# ESP32-H2 register map
Vendor: ESPRESSIF SYSTEMS (SHANGHAI) CO., LTD.; Series: ESP32 H-Series; File version: 1
CPU: RV32IMC r0p0, little endian, no MPU, no FPU, 4 interrupt priority bits
Address unit: 32 bits
Registers are 32-bit, read-write, reset 0x0 unless marked. A register's access mark holds for its fields unless they carry their own. Offsets are from the block's base; [hi:lo] are bit positions; {n}, {i} and the like mark numbered series.

## SPI2 — SPI (Serial Peripheral Interface) Controller
Base 0x60024000
Same registers: SPI3 0x60025000, SPI4 0x60037000
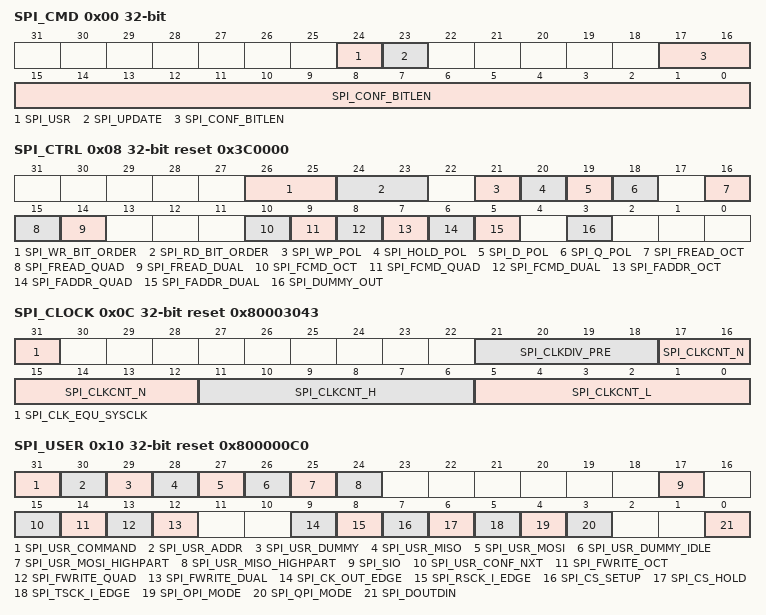
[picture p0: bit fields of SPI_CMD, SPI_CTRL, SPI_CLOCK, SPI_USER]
0x00 SPI_CMD access per field — Command control register
  [24] SPI_USR rw — User define command enable. An operation will be triggered when the bit is set. The bit will be cleared once the operation done.1: enable 0: disable. Can not be changed by CONF_buf.
  [23] SPI_UPDATE wo — Set this bit to synchronize SPI registers from APB clock domain into SPI module clock domain, which is only used in SPI master mode.
  [17:0] SPI_CONF_BITLEN rw — Define the APB cycles of SPI_CONF state. Can be configured in CONF state.
0x04 SPI_ADDR — Address value register
  [31:0] SPI_USR_ADDR_VALUE — Address to slave. Can be configured in CONF state.
0x08 SPI_CTRL access per field reset 0x3C0000 — SPI control register
  [26:25] SPI_WR_BIT_ORDER rw — In command address write-data (MOSI) phases 1: LSB firs 0: MSB first. Can be configured in CONF state.
  [24:23] SPI_RD_BIT_ORDER rw — In read-data (MISO) phase 1: LSB first 0: MSB first. Can be configured in CONF state.
  [21] SPI_WP_POL rw — Write protect signal output when SPI is idle. 1: output high, 0: output low. Can be configured in CONF state.
  [20] SPI_HOLD_POL rw — SPI_HOLD output value when SPI is idle. 1: output high, 0: output low. Can be configured in CONF state.
  [19] SPI_D_POL rw — The bit is used to set MOSI line polarity, 1: high 0, low. Can be configured in CONF state.
  [18] SPI_Q_POL rw — The bit is used to set MISO line polarity, 1: high 0, low. Can be configured in CONF state.
  [16] SPI_FREAD_OCT ro — In the read operations read-data phase apply 8 signals. 1: enable 0: disable. Can be configured in CONF state.
  [15] SPI_FREAD_QUAD rw — In the read operations read-data phase apply 4 signals. 1: enable 0: disable. Can be configured in CONF state.
  [14] SPI_FREAD_DUAL rw — In the read operations, read-data phase apply 2 signals. 1: enable 0: disable. Can be configured in CONF state.
  [10] SPI_FCMD_OCT ro — Apply 8 signals during command phase 1:enable 0: disable. Can be configured in CONF state.
  [9] SPI_FCMD_QUAD rw — Apply 4 signals during command phase 1:enable 0: disable. Can be configured in CONF state.
  [8] SPI_FCMD_DUAL rw — Apply 2 signals during command phase 1:enable 0: disable. Can be configured in CONF state.
  [7] SPI_FADDR_OCT ro — Apply 8 signals during addr phase 1:enable 0: disable. Can be configured in CONF state.
  [6] SPI_FADDR_QUAD rw — Apply 4 signals during addr phase 1:enable 0: disable. Can be configured in CONF state.
  [5] SPI_FADDR_DUAL rw — Apply 2 signals during addr phase 1:enable 0: disable. Can be configured in CONF state.
  [3] SPI_DUMMY_OUT rw — 0: In the dummy phase, the FSPI bus signals are not output. 1: In the dummy phase, the FSPI bus signals are output. Can be configured in CONF state.
0x0C SPI_CLOCK reset 0x80003043 — SPI clock control register
  [31] SPI_CLK_EQU_SYSCLK — In the master mode 1: spi_clk is eqaul to system 0: spi_clk is divided from system clock. Can be configured in CONF state.
  [21:18] SPI_CLKDIV_PRE — In the master mode it is pre-divider of spi_clk. Can be configured in CONF state.
  [17:12] SPI_CLKCNT_N — In the master mode it is the divider of spi_clk. So spi_clk frequency is system/(spi_clkdiv_pre+1)/(spi_clkcnt_N+1). Can be configured in CONF state.
  [11:6] SPI_CLKCNT_H — In the master mode it must be floor((spi_clkcnt_N+1)/2-1). In the slave mode it must be 0. Can be configured in CONF state.
  [5:0] SPI_CLKCNT_L — In the master mode it must be equal to spi_clkcnt_N. In the slave mode it must be 0. Can be configured in CONF state.
0x10 SPI_USER access per field reset 0x800000C0 — SPI USER control register
  [31] SPI_USR_COMMAND rw — This bit enable the command phase of an operation. Can be configured in CONF state.
  [30] SPI_USR_ADDR rw — This bit enable the address phase of an operation. Can be configured in CONF state.
  [29] SPI_USR_DUMMY rw — This bit enable the dummy phase of an operation. Can be configured in CONF state.
  [28] SPI_USR_MISO rw — This bit enable the read-data phase of an operation. Can be configured in CONF state.
  [27] SPI_USR_MOSI rw — This bit enable the write-data phase of an operation. Can be configured in CONF state.
  [26] SPI_USR_DUMMY_IDLE rw — spi clock is disable in dummy phase when the bit is enable. Can be configured in CONF state.
  [25] SPI_USR_MOSI_HIGHPART rw — write-data phase only access to high-part of the buffer spi_w8~spi_w15. 1: enable 0: disable. Can be configured in CONF state.
  [24] SPI_USR_MISO_HIGHPART rw — read-data phase only access to high-part of the buffer spi_w8~spi_w15. 1: enable 0: disable. Can be configured in CONF state.
  [17] SPI_SIO rw — Set the bit to enable 3-line half duplex communication mosi and miso signals share the same pin. 1: enable 0: disable. Can be configured in CONF state.
  [15] SPI_USR_CONF_NXT rw — 1: Enable the DMA CONF phase of next seg-trans operation, which means seg-trans will continue. 0: The seg-trans will end after the current SPI seg-trans or this is not seg-trans mode. Can be configured in CONF state.
  [14] SPI_FWRITE_OCT ro — In the write operations read-data phase apply 8 signals. Can be configured in CONF state.
  [13] SPI_FWRITE_QUAD rw — In the write operations read-data phase apply 4 signals. Can be configured in CONF state.
  [12] SPI_FWRITE_DUAL rw — In the write operations read-data phase apply 2 signals. Can be configured in CONF state.
  [9] SPI_CK_OUT_EDGE rw — the bit combined with spi_mosi_delay_mode bits to set mosi signal delay mode. Can be configured in CONF state.
  [8] SPI_RSCK_I_EDGE rw — In the slave mode, this bit can be used to change the polarity of rsck. 0: rsck = !spi_ck_i. 1:rsck = spi_ck_i.
  [7] SPI_CS_SETUP rw — spi cs is enable when spi is in prepare phase. 1: enable 0: disable. Can be configured in CONF state.
  [6] SPI_CS_HOLD rw — spi cs keep low when spi is in done phase. 1: enable 0: disable. Can be configured in CONF state.
  [5] SPI_TSCK_I_EDGE rw — In the slave mode, this bit can be used to change the polarity of tsck. 0: tsck = spi_ck_i. 1:tsck = !spi_ck_i.
  [4] SPI_OPI_MODE ro — Just for master mode. 1: spi controller is in OPI mode (all in 8-b-m). 0: others. Can be configured in CONF state.
  [3] SPI_QPI_MODE rw — Both for master mode and slave mode. 1: spi controller is in QPI mode. 0: others. Can be configured in CONF state.
  [0] SPI_DOUTDIN rw — Set the bit to enable full duplex communication. 1: enable 0: disable. Can be configured in CONF state.
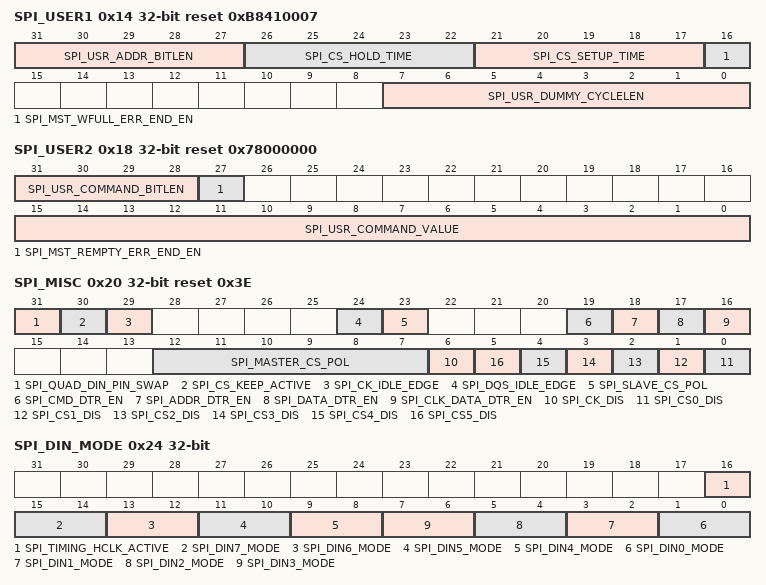
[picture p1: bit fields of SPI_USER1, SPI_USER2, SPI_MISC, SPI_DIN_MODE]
0x14 SPI_USER1 reset 0xB8410007 — SPI USER control register 1
  [31:27] SPI_USR_ADDR_BITLEN — The length in bits of address phase. The register value shall be (bit_num-1). Can be configured in CONF state.
  [26:22] SPI_CS_HOLD_TIME — delay cycles of cs pin by spi clock this bits are combined with spi_cs_hold bit. Can be configured in CONF state.
  [21:17] SPI_CS_SETUP_TIME — (cycles+1) of prepare phase by spi clock this bits are combined with spi_cs_setup bit. Can be configured in CONF state.
  [16] SPI_MST_WFULL_ERR_END_EN — 1: SPI transfer is ended when SPI RX AFIFO wfull error is valid in GP-SPI master FD/HD-mode. 0: SPI transfer is not ended when SPI RX AFIFO wfull error is valid in GP-SPI master FD/HD-mode.
  [7:0] SPI_USR_DUMMY_CYCLELEN — The length in spi_clk cycles of dummy phase. The register value shall be (cycle_num-1). Can be configured in CONF state.
0x18 SPI_USER2 reset 0x78000000 — SPI USER control register 2
  [31:28] SPI_USR_COMMAND_BITLEN — The length in bits of command phase. The register value shall be (bit_num-1). Can be configured in CONF state.
  [27] SPI_MST_REMPTY_ERR_END_EN — 1: SPI transfer is ended when SPI TX AFIFO read empty error is valid in GP-SPI master FD/HD-mode. 0: SPI transfer is not ended when SPI TX AFIFO read empty error is valid in GP-SPI master FD/HD-mode.
  [15:0] SPI_USR_COMMAND_VALUE — The value of command. Can be configured in CONF state.
0x1C SPI_MS_DLEN — SPI data bit length control register
  [17:0] SPI_MS_DATA_BITLEN — The value of these bits is the configured SPI transmission data bit length in master mode DMA controlled transfer or CPU controlled transfer. The value is also the configured bit length in slave mode DMA RX controlled transfer. The register value shall be (bit_num-1). Can be configured in CONF state.
0x20 SPI_MISC access per field reset 0x3E
  [31] SPI_QUAD_DIN_PIN_SWAP rw — 1: SPI quad input swap enable, swap FSPID with FSPIQ, swap FSPIWP with FSPIHD. 0: spi quad input swap disable. Can be configured in CONF state.
  [30] SPI_CS_KEEP_ACTIVE rw — spi cs line keep low when the bit is set. Can be configured in CONF state.
  [29] SPI_CK_IDLE_EDGE rw — 1: spi clk line is high when idle 0: spi clk line is low when idle. Can be configured in CONF state.
  [24] SPI_DQS_IDLE_EDGE ro — The default value of spi_dqs. Can be configured in CONF state.
  [23] SPI_SLAVE_CS_POL rw — spi slave input cs polarity select. 1: inv 0: not change. Can be configured in CONF state.
  [19] SPI_CMD_DTR_EN ro — 1: SPI clk and data of SPI_SEND_CMD state are in DTR mode, including master 1/2/4/8-bm. 0: SPI clk and data of SPI_SEND_CMD state are in STR mode. Can be configured in CONF state.
  [18] SPI_ADDR_DTR_EN ro — 1: SPI clk and data of SPI_SEND_ADDR state are in DTR mode, including master 1/2/4/8-bm. 0: SPI clk and data of SPI_SEND_ADDR state are in STR mode. Can be configured in CONF state.
  [17] SPI_DATA_DTR_EN ro — 1: SPI clk and data of SPI_DOUT and SPI_DIN state are in DTR mode, including master 1/2/4/8-bm. 0: SPI clk and data of SPI_DOUT and SPI_DIN state are in STR mode. Can be configured in CONF state.
  [16] SPI_CLK_DATA_DTR_EN ro — 1: SPI master DTR mode is applied to SPI clk, data and spi_dqs. 0: SPI master DTR mode is only applied to spi_dqs. This bit should be used with bit 17/18/19.
  [12:7] SPI_MASTER_CS_POL rw — In the master mode the bits are the polarity of spi cs line, the value is equivalent to spi_cs ^ spi_master_cs_pol. Can be configured in CONF state.
  [6] SPI_CK_DIS rw — 1: spi clk out disable, 0: spi clk out enable. Can be configured in CONF state.
  [n] SPI_CS{n}_DIS rw (n=0..5) — SPI CS{n} pin enable, 1: disable CS{n}, 0: spi_cs{n} signal is from/to CS{n} pin. Can be configured in CONF state.
0x24 SPI_DIN_MODE access per field — SPI input delay mode configuration
  [16] SPI_TIMING_HCLK_ACTIVE rw — 1:enable hclk in SPI input timing module. 0: disable it. Can be configured in CONF state.
  [15:14] SPI_DIN7_MODE ro — the input signals are delayed by SPI module clock cycles, 0: input without delayed, 1: input at the (SPI_DIN7_NUM+1)th falling edge of clk_spi_mst,2 input at the (SPI_DIN7_NUM+1)th rising edge of clk_hclk plus one clk_spi_mst rising edge cycle, 3: input at the (SPI_DIN7_NUM+1)th rising edge of clk_hclk plus one clk_spi_mst falling edge cycle. Can be configured in CONF state.
  [13:12] SPI_DIN6_MODE ro — the input signals are delayed by SPI module clock cycles, 0: input without delayed, 1: input at the (SPI_DIN6_NUM+1)th falling edge of clk_spi_mst,2 input at the (SPI_DIN6_NUM+1)th rising edge of clk_hclk plus one clk_spi_mst rising edge cycle, 3: input at the (SPI_DIN6_NUM+1)th rising edge of clk_hclk plus one clk_spi_mst falling edge cycle. Can be configured in CONF state.
  [11:10] SPI_DIN5_MODE ro — the input signals are delayed by SPI module clock cycles, 0: input without delayed, 1: input at the (SPI_DIN5_NUM+1)th falling edge of clk_spi_mst,2 input at the (SPI_DIN5_NUM+1)th rising edge of clk_hclk plus one clk_spi_mst rising edge cycle, 3: input at the (SPI_DIN5_NUM+1)th rising edge of clk_hclk plus one clk_spi_mst falling edge cycle. Can be configured in CONF state.
  [9:8] SPI_DIN4_MODE ro — the input signals are delayed by SPI module clock cycles, 0: input without delayed, 1: input with the posedge of clk_apb,2 input with the negedge of clk_apb, 3: input with the spi_clk. Can be configured in CONF state.
  [2n+1:2n] SPI_DIN{n}_MODE rw (n=0..3) — the input signals are delayed by SPI module clock cycles, 0: input without delayed, 1: input with the posedge of clk_apb,2 input with the negedge of clk_apb, 3: input with the spi_clk. Can be configured in CONF state.
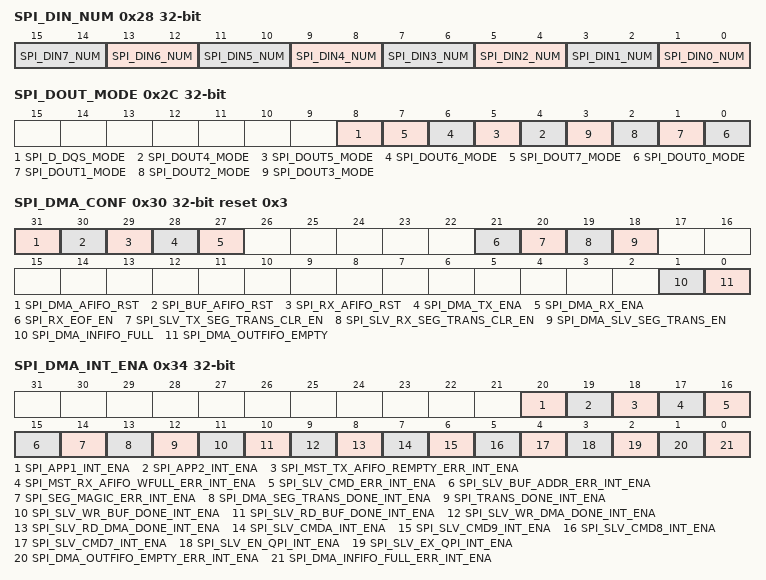
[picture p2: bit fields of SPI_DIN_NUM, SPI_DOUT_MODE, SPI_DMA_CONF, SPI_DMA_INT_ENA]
0x28 SPI_DIN_NUM access per field — SPI input delay number configuration
  [2n+1:2n] SPI_DIN{n}_NUM ro (n=4..7) — the input signals are delayed by SPI module clock cycles, 0: delayed by 1 cycle, 1: delayed by 2 cycles,... Can be configured in CONF state.
  [2n+1:2n] SPI_DIN{n}_NUM rw (n=0..3) — the input signals are delayed by SPI module clock cycles, 0: delayed by 1 cycle, 1: delayed by 2 cycles,... Can be configured in CONF state.
0x2C SPI_DOUT_MODE access per field — SPI output delay mode configuration
  [8] SPI_D_DQS_MODE ro — The output signal SPI_DQS is delayed by the SPI module clock, 0: output without delayed, 1: output delay for a SPI module clock cycle at its negative edge. Can be configured in CONF state.
  [n] SPI_DOUT{n}_MODE ro (n=4..7) — The output signal {n} is delayed by the SPI module clock, 0: output without delayed, 1: output delay for a SPI module clock cycle at its negative edge. Can be configured in CONF state.
  [n] SPI_DOUT{n}_MODE rw (n=0..3) — The output signal {n} is delayed by the SPI module clock, 0: output without delayed, 1: output delay for a SPI module clock cycle at its negative edge. Can be configured in CONF state.
0x30 SPI_DMA_CONF access per field reset 0x3 — SPI DMA control register
  [31] SPI_DMA_AFIFO_RST wo — Set this bit to reset DMA TX AFIFO, which is used to send data out in SPI slave DMA controlled mode transfer.
  [30] SPI_BUF_AFIFO_RST wo — Set this bit to reset BUF TX AFIFO, which is used send data out in SPI slave CPU controlled mode transfer and master mode transfer.
  [29] SPI_RX_AFIFO_RST wo — Set this bit to reset RX AFIFO, which is used to receive data in SPI master and slave mode transfer.
  [28] SPI_DMA_TX_ENA rw — Set this bit to enable SPI DMA controlled send data mode.
  [27] SPI_DMA_RX_ENA rw — Set this bit to enable SPI DMA controlled receive data mode.
  [21] SPI_RX_EOF_EN rw — 1: spi_dma_inlink_eof is set when the number of dma pushed data bytes is equal to the value of spi_slv/mst_dma_rd_bytelen[19:0] in spi dma transition. 0: spi_dma_inlink_eof is set by spi_trans_done in non-seg-trans or spi_dma_seg_trans_done in seg-trans.
  [20] SPI_SLV_TX_SEG_TRANS_CLR_EN rw — 1: spi_dma_outfifo_empty_vld is cleared by spi slave cmd 6. 0: spi_dma_outfifo_empty_vld is cleared by spi_trans_done.
  [19] SPI_SLV_RX_SEG_TRANS_CLR_EN rw — 1: spi_dma_infifo_full_vld is cleared by spi slave cmd 5. 0: spi_dma_infifo_full_vld is cleared by spi_trans_done.
  [18] SPI_DMA_SLV_SEG_TRANS_EN rw — Enable dma segment transfer in spi dma half slave mode. 1: enable. 0: disable.
  [1] SPI_DMA_INFIFO_FULL ro — Records the status of DMA RX FIFO. 1: DMA RX FIFO is not ready for receiving data. 0: DMA RX FIFO is ready for receiving data.
  [0] SPI_DMA_OUTFIFO_EMPTY ro — Records the status of DMA TX FIFO. 1: DMA TX FIFO is not ready for sending data. 0: DMA TX FIFO is ready for sending data.
0x34 SPI_DMA_INT_ENA — SPI interrupt enable register
  [20] SPI_APP1_INT_ENA — The enable bit for SPI_APP1_INT interrupt.
  [19] SPI_APP2_INT_ENA — The enable bit for SPI_APP2_INT interrupt.
  [18] SPI_MST_TX_AFIFO_REMPTY_ERR_INT_ENA — The enable bit for SPI_MST_TX_AFIFO_REMPTY_ERR_INT interrupt.
  [17] SPI_MST_RX_AFIFO_WFULL_ERR_INT_ENA — The enable bit for SPI_MST_RX_AFIFO_WFULL_ERR_INT interrupt.
  [16] SPI_SLV_CMD_ERR_INT_ENA — The enable bit for SPI_SLV_CMD_ERR_INT interrupt.
  [15] SPI_SLV_BUF_ADDR_ERR_INT_ENA — The enable bit for SPI_SLV_BUF_ADDR_ERR_INT interrupt.
  [14] SPI_SEG_MAGIC_ERR_INT_ENA — The enable bit for SPI_SEG_MAGIC_ERR_INT interrupt.
  [13] SPI_DMA_SEG_TRANS_DONE_INT_ENA — The enable bit for SPI_DMA_SEG_TRANS_DONE_INT interrupt.
  [12] SPI_TRANS_DONE_INT_ENA — The enable bit for SPI_TRANS_DONE_INT interrupt.
  [11] SPI_SLV_WR_BUF_DONE_INT_ENA — The enable bit for SPI_SLV_WR_BUF_DONE_INT interrupt.
  [10] SPI_SLV_RD_BUF_DONE_INT_ENA — The enable bit for SPI_SLV_RD_BUF_DONE_INT interrupt.
  [9] SPI_SLV_WR_DMA_DONE_INT_ENA — The enable bit for SPI_SLV_WR_DMA_DONE_INT interrupt.
  [8] SPI_SLV_RD_DMA_DONE_INT_ENA — The enable bit for SPI_SLV_RD_DMA_DONE_INT interrupt.
  [7] SPI_SLV_CMDA_INT_ENA — The enable bit for SPI slave CMDA interrupt.
  [6] SPI_SLV_CMD9_INT_ENA — The enable bit for SPI slave CMD9 interrupt.
  [5] SPI_SLV_CMD8_INT_ENA — The enable bit for SPI slave CMD8 interrupt.
  [4] SPI_SLV_CMD7_INT_ENA — The enable bit for SPI slave CMD7 interrupt.
  [3] SPI_SLV_EN_QPI_INT_ENA — The enable bit for SPI slave En_QPI interrupt.
  [2] SPI_SLV_EX_QPI_INT_ENA — The enable bit for SPI slave Ex_QPI interrupt.
  [1] SPI_DMA_OUTFIFO_EMPTY_ERR_INT_ENA — The enable bit for SPI_DMA_OUTFIFO_EMPTY_ERR_INT interrupt.
  [0] SPI_DMA_INFIFO_FULL_ERR_INT_ENA — The enable bit for SPI_DMA_INFIFO_FULL_ERR_INT interrupt.
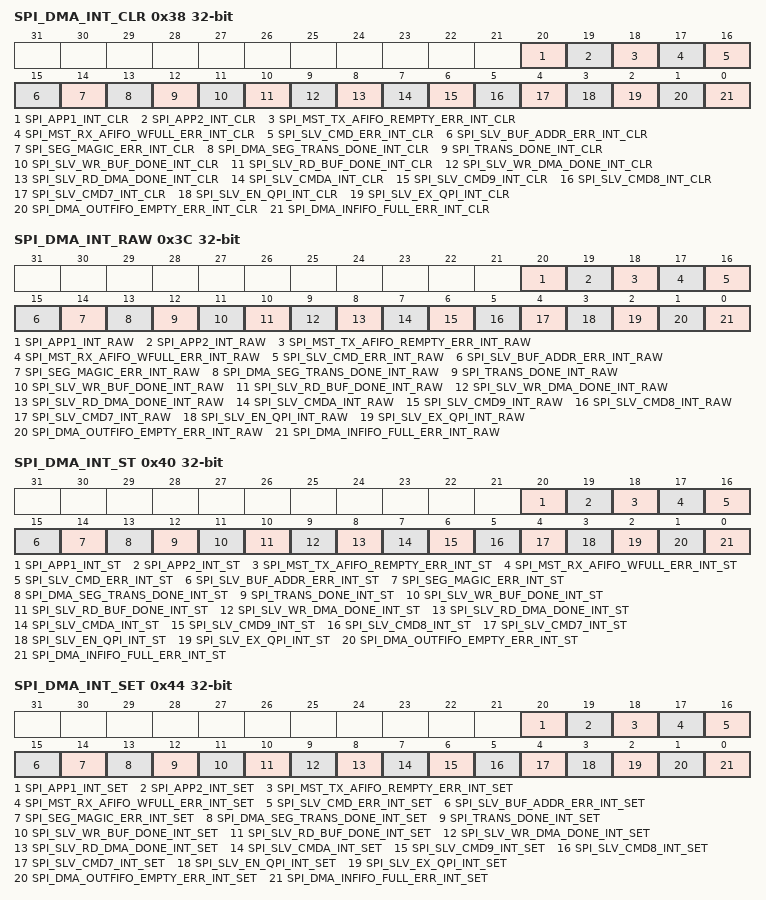
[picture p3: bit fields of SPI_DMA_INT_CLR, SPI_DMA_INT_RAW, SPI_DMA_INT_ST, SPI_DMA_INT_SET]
0x38 SPI_DMA_INT_CLR wo — SPI interrupt clear register
  [20] SPI_APP1_INT_CLR — The clear bit for SPI_APP1_INT interrupt.
  [19] SPI_APP2_INT_CLR — The clear bit for SPI_APP2_INT interrupt.
  [18] SPI_MST_TX_AFIFO_REMPTY_ERR_INT_CLR — The clear bit for SPI_MST_TX_AFIFO_REMPTY_ERR_INT interrupt.
  [17] SPI_MST_RX_AFIFO_WFULL_ERR_INT_CLR — The clear bit for SPI_MST_RX_AFIFO_WFULL_ERR_INT interrupt.
  [16] SPI_SLV_CMD_ERR_INT_CLR — The clear bit for SPI_SLV_CMD_ERR_INT interrupt.
  [15] SPI_SLV_BUF_ADDR_ERR_INT_CLR — The clear bit for SPI_SLV_BUF_ADDR_ERR_INT interrupt.
  [14] SPI_SEG_MAGIC_ERR_INT_CLR — The clear bit for SPI_SEG_MAGIC_ERR_INT interrupt.
  [13] SPI_DMA_SEG_TRANS_DONE_INT_CLR — The clear bit for SPI_DMA_SEG_TRANS_DONE_INT interrupt.
  [12] SPI_TRANS_DONE_INT_CLR — The clear bit for SPI_TRANS_DONE_INT interrupt.
  [11] SPI_SLV_WR_BUF_DONE_INT_CLR — The clear bit for SPI_SLV_WR_BUF_DONE_INT interrupt.
  [10] SPI_SLV_RD_BUF_DONE_INT_CLR — The clear bit for SPI_SLV_RD_BUF_DONE_INT interrupt.
  [9] SPI_SLV_WR_DMA_DONE_INT_CLR — The clear bit for SPI_SLV_WR_DMA_DONE_INT interrupt.
  [8] SPI_SLV_RD_DMA_DONE_INT_CLR — The clear bit for SPI_SLV_RD_DMA_DONE_INT interrupt.
  [7] SPI_SLV_CMDA_INT_CLR — The clear bit for SPI slave CMDA interrupt.
  [6] SPI_SLV_CMD9_INT_CLR — The clear bit for SPI slave CMD9 interrupt.
  [5] SPI_SLV_CMD8_INT_CLR — The clear bit for SPI slave CMD8 interrupt.
  [4] SPI_SLV_CMD7_INT_CLR — The clear bit for SPI slave CMD7 interrupt.
  [3] SPI_SLV_EN_QPI_INT_CLR — The clear bit for SPI slave En_QPI interrupt.
  [2] SPI_SLV_EX_QPI_INT_CLR — The clear bit for SPI slave Ex_QPI interrupt.
  [1] SPI_DMA_OUTFIFO_EMPTY_ERR_INT_CLR — The clear bit for SPI_DMA_OUTFIFO_EMPTY_ERR_INT interrupt.
  [0] SPI_DMA_INFIFO_FULL_ERR_INT_CLR — The clear bit for SPI_DMA_INFIFO_FULL_ERR_INT interrupt.
0x3C SPI_DMA_INT_RAW ro — SPI interrupt raw register
  [20] SPI_APP1_INT_RAW — The raw bit for SPI_APP1_INT interrupt. The value is only controlled by software.
  [19] SPI_APP2_INT_RAW — The raw bit for SPI_APP2_INT interrupt. The value is only controlled by software.
  [18] SPI_MST_TX_AFIFO_REMPTY_ERR_INT_RAW — The raw bit for SPI_MST_TX_AFIFO_REMPTY_ERR_INT interrupt. 1: There is a TX BUF AFIFO read-empty error when SPI outputs data in master mode. 0: Others.
  [17] SPI_MST_RX_AFIFO_WFULL_ERR_INT_RAW — The raw bit for SPI_MST_RX_AFIFO_WFULL_ERR_INT interrupt. 1: There is a RX AFIFO write-full error when SPI inputs data in master mode. 0: Others.
  [16] SPI_SLV_CMD_ERR_INT_RAW — The raw bit for SPI_SLV_CMD_ERR_INT interrupt. 1: The slave command value in the current SPI slave HD mode transmission is not supported. 0: Others.
  [15] SPI_SLV_BUF_ADDR_ERR_INT_RAW — The raw bit for SPI_SLV_BUF_ADDR_ERR_INT interrupt. 1: The accessing data address of the current SPI slave mode CPU controlled FD, Wr_BUF or Rd_BUF transmission is bigger than 63. 0: Others.
  [14] SPI_SEG_MAGIC_ERR_INT_RAW — The raw bit for SPI_SEG_MAGIC_ERR_INT interrupt. 1: The magic value in CONF buffer is error in the DMA seg-conf-trans. 0: others.
  [13] SPI_DMA_SEG_TRANS_DONE_INT_RAW — The raw bit for SPI_DMA_SEG_TRANS_DONE_INT interrupt. 1: spi master DMA full-duplex/half-duplex seg-conf-trans ends or slave half-duplex seg-trans ends. And data has been pushed to corresponding memory. 0: seg-conf-trans or seg-trans is not ended or not occurred.
  [12] SPI_TRANS_DONE_INT_RAW — The raw bit for SPI_TRANS_DONE_INT interrupt. 1: SPI master mode transmission is ended. 0: others.
  [11] SPI_SLV_WR_BUF_DONE_INT_RAW — The raw bit for SPI_SLV_WR_BUF_DONE_INT interrupt. 1: SPI slave mode Wr_BUF transmission is ended. 0: Others.
  [10] SPI_SLV_RD_BUF_DONE_INT_RAW — The raw bit for SPI_SLV_RD_BUF_DONE_INT interrupt. 1: SPI slave mode Rd_BUF transmission is ended. 0: Others.
  [9] SPI_SLV_WR_DMA_DONE_INT_RAW — The raw bit for SPI_SLV_WR_DMA_DONE_INT interrupt. 1: SPI slave mode Wr_DMA transmission is ended. 0: Others.
  [8] SPI_SLV_RD_DMA_DONE_INT_RAW — The raw bit for SPI_SLV_RD_DMA_DONE_INT interrupt. 1: SPI slave mode Rd_DMA transmission is ended. 0: Others.
  [7] SPI_SLV_CMDA_INT_RAW — The raw bit for SPI slave CMDA interrupt. 1: SPI slave mode CMDA transmission is ended. 0: Others.
  [6] SPI_SLV_CMD9_INT_RAW — The raw bit for SPI slave CMD9 interrupt. 1: SPI slave mode CMD9 transmission is ended. 0: Others.
  [5] SPI_SLV_CMD8_INT_RAW — The raw bit for SPI slave CMD8 interrupt. 1: SPI slave mode CMD8 transmission is ended. 0: Others.
  [4] SPI_SLV_CMD7_INT_RAW — The raw bit for SPI slave CMD7 interrupt. 1: SPI slave mode CMD7 transmission is ended. 0: Others.
  [3] SPI_SLV_EN_QPI_INT_RAW — The raw bit for SPI slave En_QPI interrupt. 1: SPI slave mode En_QPI transmission is ended. 0: Others.
  [2] SPI_SLV_EX_QPI_INT_RAW — The raw bit for SPI slave Ex_QPI interrupt. 1: SPI slave mode Ex_QPI transmission is ended. 0: Others.
  [1] SPI_DMA_OUTFIFO_EMPTY_ERR_INT_RAW — 1: The current data rate of DMA TX is smaller than that of SPI. SPI will stop in master mode and send out all 0 in slave mode. 0: Others.
  [0] SPI_DMA_INFIFO_FULL_ERR_INT_RAW — 1: The current data rate of DMA Rx is smaller than that of SPI, which will lose the receive data. 0: Others.
0x40 SPI_DMA_INT_ST ro — SPI interrupt status register
  [20] SPI_APP1_INT_ST — The status bit for SPI_APP1_INT interrupt.
  [19] SPI_APP2_INT_ST — The status bit for SPI_APP2_INT interrupt.
  [18] SPI_MST_TX_AFIFO_REMPTY_ERR_INT_ST — The status bit for SPI_MST_TX_AFIFO_REMPTY_ERR_INT interrupt.
  [17] SPI_MST_RX_AFIFO_WFULL_ERR_INT_ST — The status bit for SPI_MST_RX_AFIFO_WFULL_ERR_INT interrupt.
  [16] SPI_SLV_CMD_ERR_INT_ST — The status bit for SPI_SLV_CMD_ERR_INT interrupt.
  [15] SPI_SLV_BUF_ADDR_ERR_INT_ST — The status bit for SPI_SLV_BUF_ADDR_ERR_INT interrupt.
  [14] SPI_SEG_MAGIC_ERR_INT_ST — The status bit for SPI_SEG_MAGIC_ERR_INT interrupt.
  [13] SPI_DMA_SEG_TRANS_DONE_INT_ST — The status bit for SPI_DMA_SEG_TRANS_DONE_INT interrupt.
  [12] SPI_TRANS_DONE_INT_ST — The status bit for SPI_TRANS_DONE_INT interrupt.
  [11] SPI_SLV_WR_BUF_DONE_INT_ST — The status bit for SPI_SLV_WR_BUF_DONE_INT interrupt.
  [10] SPI_SLV_RD_BUF_DONE_INT_ST — The status bit for SPI_SLV_RD_BUF_DONE_INT interrupt.
  [9] SPI_SLV_WR_DMA_DONE_INT_ST — The status bit for SPI_SLV_WR_DMA_DONE_INT interrupt.
  [8] SPI_SLV_RD_DMA_DONE_INT_ST — The status bit for SPI_SLV_RD_DMA_DONE_INT interrupt.
  [7] SPI_SLV_CMDA_INT_ST — The status bit for SPI slave CMDA interrupt.
  [6] SPI_SLV_CMD9_INT_ST — The status bit for SPI slave CMD9 interrupt.
  [5] SPI_SLV_CMD8_INT_ST — The status bit for SPI slave CMD8 interrupt.
  [4] SPI_SLV_CMD7_INT_ST — The status bit for SPI slave CMD7 interrupt.
  [3] SPI_SLV_EN_QPI_INT_ST — The status bit for SPI slave En_QPI interrupt.
  [2] SPI_SLV_EX_QPI_INT_ST — The status bit for SPI slave Ex_QPI interrupt.
  [1] SPI_DMA_OUTFIFO_EMPTY_ERR_INT_ST — The status bit for SPI_DMA_OUTFIFO_EMPTY_ERR_INT interrupt.
  [0] SPI_DMA_INFIFO_FULL_ERR_INT_ST — The status bit for SPI_DMA_INFIFO_FULL_ERR_INT interrupt.
0x44 SPI_DMA_INT_SET wo — SPI interrupt software set register
  [20] SPI_APP1_INT_SET — The software set bit for SPI_APP1_INT interrupt.
  [19] SPI_APP2_INT_SET — The software set bit for SPI_APP2_INT interrupt.
  [18] SPI_MST_TX_AFIFO_REMPTY_ERR_INT_SET — The software set bit for SPI_MST_TX_AFIFO_REMPTY_ERR_INT interrupt.
  [17] SPI_MST_RX_AFIFO_WFULL_ERR_INT_SET — The software set bit for SPI_MST_RX_AFIFO_WFULL_ERR_INT interrupt.
  [16] SPI_SLV_CMD_ERR_INT_SET — The software set bit for SPI_SLV_CMD_ERR_INT interrupt.
  [15] SPI_SLV_BUF_ADDR_ERR_INT_SET — The software set bit for SPI_SLV_BUF_ADDR_ERR_INT interrupt.
  [14] SPI_SEG_MAGIC_ERR_INT_SET — The software set bit for SPI_SEG_MAGIC_ERR_INT interrupt.
  [13] SPI_DMA_SEG_TRANS_DONE_INT_SET — The software set bit for SPI_DMA_SEG_TRANS_DONE_INT interrupt.
  [12] SPI_TRANS_DONE_INT_SET — The software set bit for SPI_TRANS_DONE_INT interrupt.
  [11] SPI_SLV_WR_BUF_DONE_INT_SET — The software set bit for SPI_SLV_WR_BUF_DONE_INT interrupt.
  [10] SPI_SLV_RD_BUF_DONE_INT_SET — The software set bit for SPI_SLV_RD_BUF_DONE_INT interrupt.
  [9] SPI_SLV_WR_DMA_DONE_INT_SET — The software set bit for SPI_SLV_WR_DMA_DONE_INT interrupt.
  [8] SPI_SLV_RD_DMA_DONE_INT_SET — The software set bit for SPI_SLV_RD_DMA_DONE_INT interrupt.
  [7] SPI_SLV_CMDA_INT_SET — The software set bit for SPI slave CMDA interrupt.
  [6] SPI_SLV_CMD9_INT_SET — The software set bit for SPI slave CMD9 interrupt.
  [5] SPI_SLV_CMD8_INT_SET — The software set bit for SPI slave CMD8 interrupt.
  [4] SPI_SLV_CMD7_INT_SET — The software set bit for SPI slave CMD7 interrupt.
  [3] SPI_SLV_EN_QPI_INT_SET — The software set bit for SPI slave En_QPI interrupt.
  [2] SPI_SLV_EX_QPI_INT_SET — The software set bit for SPI slave Ex_QPI interrupt.
  [1] SPI_DMA_OUTFIFO_EMPTY_ERR_INT_SET — The software set bit for SPI_DMA_OUTFIFO_EMPTY_ERR_INT interrupt.
  [0] SPI_DMA_INFIFO_FULL_ERR_INT_SET — The software set bit for SPI_DMA_INFIFO_FULL_ERR_INT interrupt.
{0x98+4i} SPI_W{i} (i=0..15) — SPI CPU-controlled buffer{i}
  [31:0] SPI_BUF{i} — data buffer
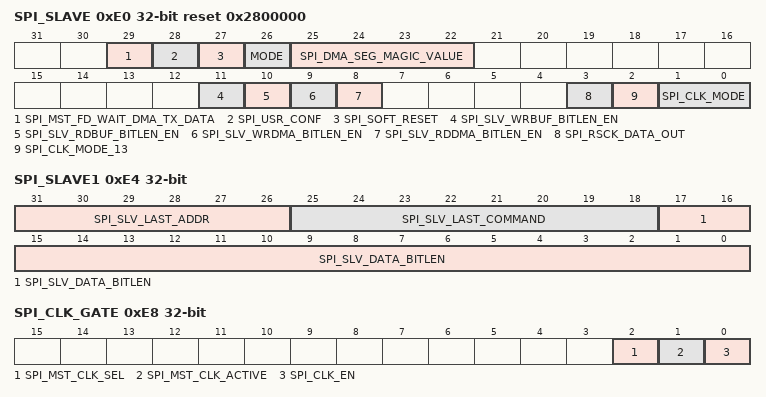
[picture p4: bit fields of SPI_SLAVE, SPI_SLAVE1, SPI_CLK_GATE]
0xE0 SPI_SLAVE access per field reset 0x2800000 — SPI slave control register
  [29] SPI_MST_FD_WAIT_DMA_TX_DATA rw — In master full-duplex mode, 1: GP-SPI will wait DMA TX data is ready before starting SPI transfer. 0: GP-SPI does not wait DMA TX data before starting SPI transfer.
  [28] SPI_USR_CONF rw — 1: Enable the DMA CONF phase of current seg-trans operation, which means seg-trans will start. 0: This is not seg-trans mode.
  [27] SPI_SOFT_RESET wo — Software reset enable, reset the spi clock line cs line and data lines. Can be configured in CONF state.
  [26] MODE rw — Set SPI work mode. 1: slave mode 0: master mode.
  [25:22] SPI_DMA_SEG_MAGIC_VALUE rw — The magic value of BM table in master DMA seg-trans.
  [11] SPI_SLV_WRBUF_BITLEN_EN rw — 1: SPI_SLV_DATA_BITLEN stores data bit length of master-write-to-slave data length in CPU controlled mode(Wr_BUF). 0: others
  [10] SPI_SLV_RDBUF_BITLEN_EN rw — 1: SPI_SLV_DATA_BITLEN stores data bit length of master-read-slave data length in CPU controlled mode(Rd_BUF). 0: others
  [9] SPI_SLV_WRDMA_BITLEN_EN rw — 1: SPI_SLV_DATA_BITLEN stores data bit length of master-write-to-slave data length in DMA controlled mode(Wr_DMA). 0: others
  [8] SPI_SLV_RDDMA_BITLEN_EN rw — 1: SPI_SLV_DATA_BITLEN stores data bit length of master-read-slave data length in DMA controlled mode(Rd_DMA). 0: others
  [3] SPI_RSCK_DATA_OUT rw — It saves half a cycle when tsck is the same as rsck. 1: output data at rsck posedge 0: output data at tsck posedge
  [2] SPI_CLK_MODE_13 rw — {CPOL, CPHA},1: support spi clk mode 1 and 3, first edge output data B[0]/B[7]. 0: support spi clk mode 0 and 2, first edge output data B[1]/B[6].
  [1:0] SPI_CLK_MODE rw — SPI clock mode bits. 0: SPI clock is off when CS inactive 1: SPI clock is delayed one cycle after CS inactive 2: SPI clock is delayed two cycles after CS inactive 3: SPI clock is alwasy on. Can be configured in CONF state.
0xE4 SPI_SLAVE1 — SPI slave control register 1
  [31:26] SPI_SLV_LAST_ADDR — In the slave mode it is the value of address.
  [25:18] SPI_SLV_LAST_COMMAND — In the slave mode it is the value of command.
  [17:0] SPI_SLV_DATA_BITLEN — The transferred data bit length in SPI slave FD and HD mode.
0xE8 SPI_CLK_GATE — SPI module clock and register clock control
  [2] SPI_MST_CLK_SEL — This bit is used to select SPI module clock source in master mode. 1: PLL_CLK_80M. 0: XTAL CLK.
  [1] SPI_MST_CLK_ACTIVE — Set this bit to power on the SPI module clock.
  [0] SPI_CLK_EN — Set this bit to enable clk gate
0xF0 SPI_DATE reset 0x2201300 — Version control
  [27:0] SPI_DATE — SPI register version.
